# HDSC_HC32L156JX register map
Vendor: HDSC Co.Ltd; Series: ARMCM0P; File version: 1.2
CPU: CM0 r0p0, little endian, no MPU, no FPU, 3 interrupt priority bits
Registers are 8-bit, read-write, reset 0x0 unless marked. A register's access mark holds for its fields unless they carry their own. Offsets are from the block's base; [hi:lo] are bit positions; {n}, {i} and the like mark numbered series.

## HWWDT
Base 0x40011000
0x00 WDT_LD 32-bit reset 0xFFFF
0x04 WDT_VL 32-bit ro
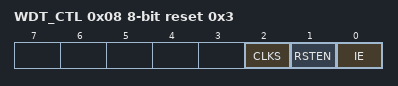
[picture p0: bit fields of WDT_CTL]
0x08 WDT_CTL reset 0x3
  [2] CLKS, [1] RSTEN, [0] IE
0x0C WDT_INTCLR
0x10 WDT_STA ro
  [0] STA
0x14 WDT_LCK 32-bit reset 0x1

## IRQC
Base 0x40031000
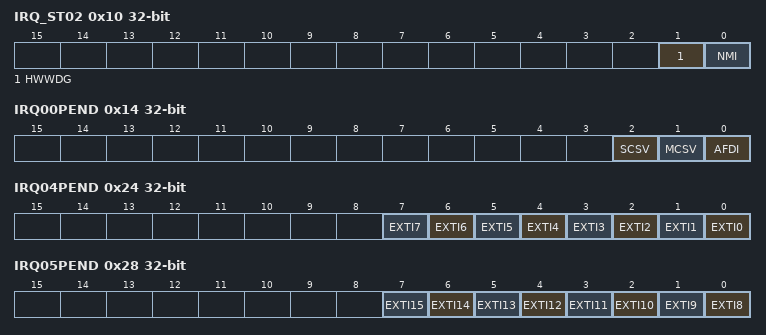
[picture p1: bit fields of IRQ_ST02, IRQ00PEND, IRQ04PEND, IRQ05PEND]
0x10 IRQ_ST02 32-bit ro
  [1] HWWDG, [0] NMI
0x14 IRQ00PEND 32-bit ro
  [2] SCSV, [1] MCSV, [0] AFDI
0x18 IRQ01PEND 32-bit ro
  [0] SWWDG
0x1C IRQ02PEND 32-bit ro
  [0] LVD
0x24 IRQ04PEND 32-bit ro
  [n] EXTI{n} (n=0..7)
0x28 IRQ05PEND 32-bit ro
  [n-8] EXTI{n} (n=8..15)
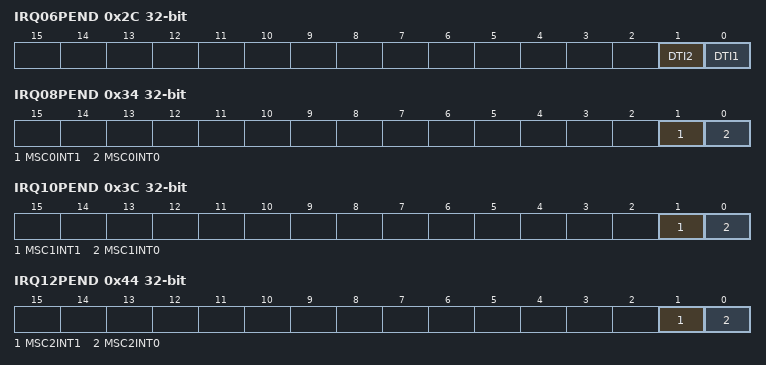
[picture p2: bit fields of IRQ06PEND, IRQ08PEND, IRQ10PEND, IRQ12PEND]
0x2C IRQ06PEND 32-bit ro
  [1] DTI2, [0] DTI1
0x30 IRQ07PEND 32-bit ro
  [0] MSC0INT
0x34 IRQ08PEND 32-bit ro
  [1] MSC0INT1, [0] MSC0INT0
0x38 IRQ09PEND 32-bit ro
  [0] MSC1INT
0x3C IRQ10PEND 32-bit ro
  [1] MSC1INT1, [0] MSC1INT0
0x40 IRQ11PEND 32-bit ro
  [0] MSC2INT
0x44 IRQ12PEND 32-bit ro
  [1] MSC2INT1, [0] MSC2INT0
0x50 IRQ15PEND 32-bit ro
  [0] MSC4INT
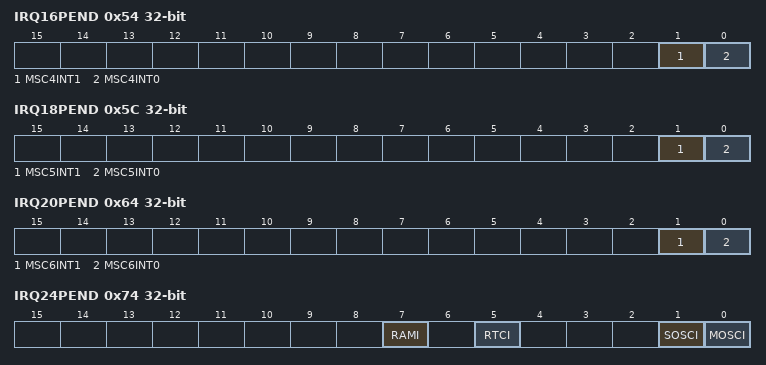
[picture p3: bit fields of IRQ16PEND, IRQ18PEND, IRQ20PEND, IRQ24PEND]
0x54 IRQ16PEND 32-bit ro
  [1] MSC4INT1, [0] MSC4INT0
0x58 IRQ17PEND 32-bit ro
  [0] MSC5INT
0x5C IRQ18PEND 32-bit ro
  [1] MSC5INT1, [0] MSC5INT0
0x60 IRQ19PEND 32-bit ro
  [0] MSC6INT
0x64 IRQ20PEND 32-bit ro
  [1] MSC6INT1, [0] MSC6INT0
0x74 IRQ24PEND 32-bit ro
  [7] RAMI, [5] RTCI, [1] SOSCI, [0] MOSCI
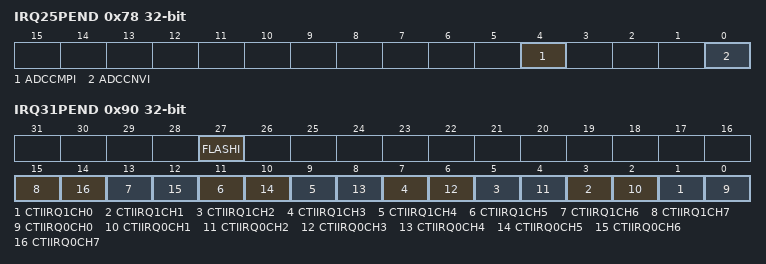
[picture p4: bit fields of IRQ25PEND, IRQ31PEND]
0x78 IRQ25PEND 32-bit ro
  [4] ADCCMPI, [0] ADCCNVI
0x7C IRQ26PEND 32-bit ro
  [5] VCI
0x80 IRQ27PEND 32-bit ro
  [6] ICCI
0x90 IRQ31PEND 32-bit ro
  [27] FLASHI, [2n+1] CTIIRQ1CH{n} (n=0..7), [2n] CTIIRQ0CH{n} (n=0..7)

## LCDC
Base 0x40032000
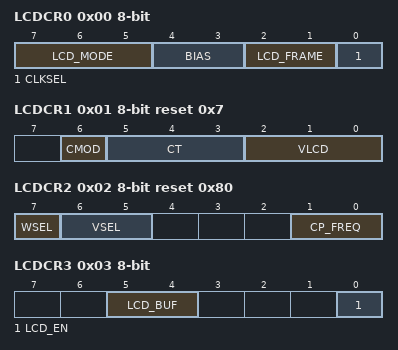
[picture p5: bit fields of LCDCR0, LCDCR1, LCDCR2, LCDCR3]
0x00 LCDCR0
  [7:5] LCD_MODE, [4:3] BIAS, [2:1] LCD_FRAME, [0] CLKSEL
0x01 LCDCR1 reset 0x7
  [6] CMOD, [5:3] CT, [2:0] VLCD
0x02 LCDCR2 reset 0x80
  [7] WSEL, [6:5] VSEL, [1:0] CP_FREQ
0x03 LCDCR3
  [5:4] LCD_BUF, [0] LCD_EN
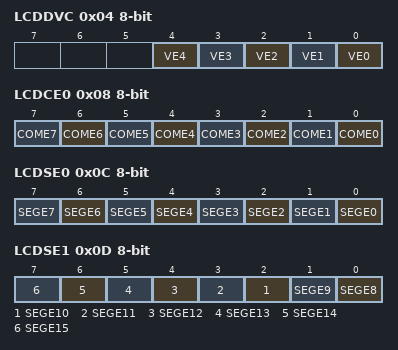
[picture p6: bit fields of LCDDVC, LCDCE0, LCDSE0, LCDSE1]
0x04 LCDDVC
  [n] VE{n} (n=0..4)
0x08 LCDCE0
  [n] COME{n} (n=0..7)
0x0C LCDSE0
  [n] SEGE{n} (n=0..7)
0x0D LCDSE1
  [n-8] SEGE{n} (n=8..15)
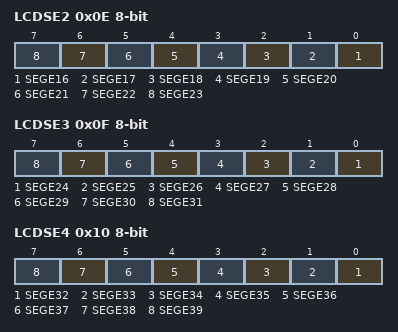
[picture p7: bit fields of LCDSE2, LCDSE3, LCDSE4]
0x0E LCDSE2
  [n-16] SEGE{n} (n=16..23)
0x0F LCDSE3
  [n-24] SEGE{n} (n=24..31)
0x10 LCDSE4
  [n-32] SEGE{n} (n=32..39)
{0x14+i} LCDRAM{i:02} (i=0..39)

## MSC0_I2C — desc MSC_I2C
Base 0x40038000
Same registers: MSC4_I2C 0x40037000, MSC5_I2C 0x40037100, MSC6_I2C 0x40037200, MSC1_I2C 0x40038100, MSC2_I2C 0x40038200
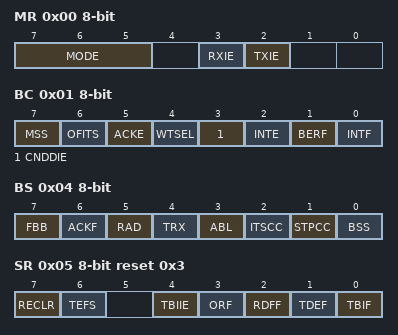
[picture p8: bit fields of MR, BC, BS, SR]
0x00 MR
  [7:5] MODE, [3] RXIE, [2] TXIE
0x01 BC
  [7] MSS, [6] OFITS, [5] ACKE, [4] WTSEL, [3] CNDDIE, [2] INTE, [1] BERF ro, [0] INTF
0x04 BS
  [7] FBB ro, [6] ACKF ro, [5] RAD ro, [4] TRX ro, [3] ABL ro, [2] ITSCC, [1] STPCC, [0] BSS ro
0x05 SR reset 0x3
  [7] RECLR, [6] TEFS, [4] TBIIE, [3] ORF ro, [2] RDFF ro, [1] TDEF ro, [0] TBIF ro
0x08 RXDR 16-bit ro (reset mask 0xFF)
0x08 TXDR 16-bit wo reset 0xFF (reset mask 0xFF)
0x0C BRS 16-bit
  [14:0] BRS
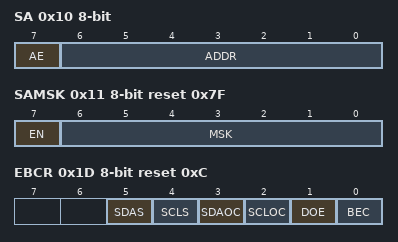
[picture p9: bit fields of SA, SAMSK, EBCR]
0x10 SA
  [7] AE, [6:0] ADDR
0x11 SAMSK reset 0x7F
  [7] EN, [6:0] MSK
0x1D EBCR reset 0xC
  [5] SDAS ro, [4] SCLS ro, [3] SDAOC, [2] SCLOC, [1] DOE, [0] BEC

## MSC0_SPI — desc MSC_SPI
Base 0x40038000; alternate view of MSC0_I2C
Same registers: MSC4_SPI 0x40037000 (alternate view of MSC4_I2C), MSC5_SPI 0x40037100 (alternate view of MSC5_I2C), MSC6_SPI 0x40037200 (alternate view of MSC6_I2C), MSC1_SPI 0x40038100 (alternate view of MSC1_I2C), MSC2_SPI 0x40038200 (alternate view of MSC2_I2C)
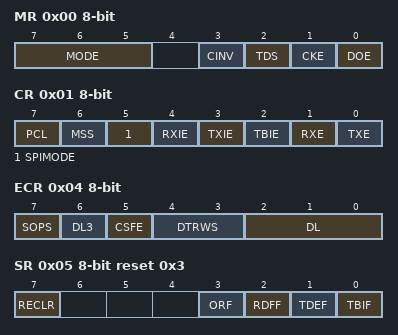
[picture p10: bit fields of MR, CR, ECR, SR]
0x00 MR
  [7:5] MODE, [3] CINV, [2] TDS, [1] CKE, [0] DOE
0x01 CR
  [7] PCL, [6] MSS, [5] SPIMODE, [4] RXIE, [3] TXIE, [2] TBIE, [1] RXE, [0] TXE
0x04 ECR
  [7] SOPS, [6] DL3, [5] CSFE, [4:3] DTRWS, [2:0] DL
0x05 SR reset 0x3
  [7] RECLR, [3] ORF ro, [2] RDFF ro, [1] TDEF ro, [0] TBIF ro
0x08 RXDR 16-bit ro
0x08 TXDR 16-bit wo reset 0xFFFF
0x0C BRS 16-bit
  [14:0] BRS
0x1C CSTMG0
  [7:0] CSHDLY
0x1D CSTMG1
  [7:0] CSSDLY
0x20 CSTMG32 16-bit
  [15:0] CSDS
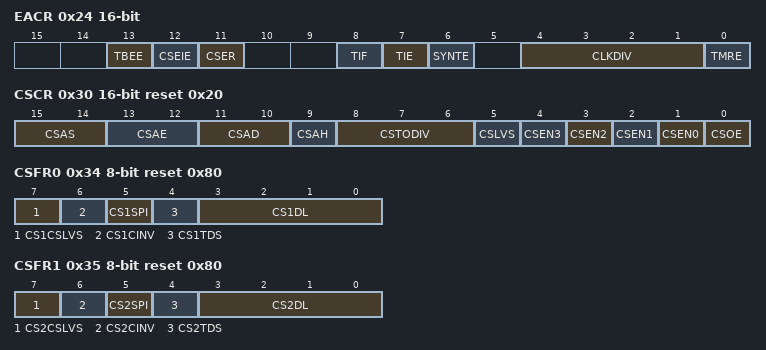
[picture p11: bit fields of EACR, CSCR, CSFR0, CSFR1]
0x24 EACR 16-bit
  [13] TBEE, [12] CSEIE, [11] CSER, [8] TIF, [7] TIE, [6] SYNTE, [4:1] CLKDIV, [0] TMRE
0x28 TMR 16-bit ro
0x2C TMC 16-bit
0x30 CSCR 16-bit reset 0x20
  [15:14] CSAS, [13:12] CSAE, [11:10] CSAD ro, [9] CSAH, [8:6] CSTODIV, [5] CSLVS, [n+1] CSEN{n} (n=0..3), [0] CSOE
0x34 CSFR0 reset 0x80
  [7] CS1CSLVS, [6] CS1CINV, [5] CS1SPI, [4] CS1TDS, [3:0] CS1DL
0x35 CSFR1 reset 0x80
  [7] CS2CSLVS, [6] CS2CINV, [5] CS2SPI, [4] CS2TDS, [3:0] CS2DL
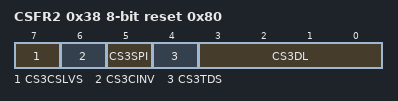
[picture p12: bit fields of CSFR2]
0x38 CSFR2 reset 0x80
  [7] CS3CSLVS, [6] CS3CINV, [5] CS3SPI, [4] CS3TDS, [3:0] CS3DL
0x3C TDTCNT0
0x3D TDTCNT1
0x40 TDTCNT2
0x41 TDTCNT3
